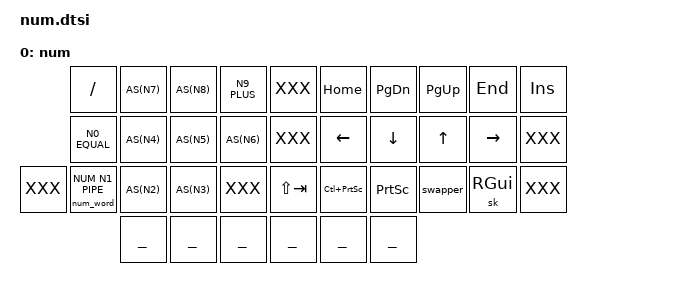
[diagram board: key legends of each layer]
/**
 * Numeric / Navigation Layer
 */

/ {
    keymap {
        compatible = "zmk,keymap";

        num {
            display-name = "num";
            bindings = <
//                ╭─────────────┬─────────────┬─────────────┬─────────────┬─────────────╮   ╭─────────────┬─────────────┬─────────────┬─────────────┬─────────────╮
                   &kp FSLH      AS(N7)        AS(N8)        N9_PLUS       XXX               &kp HOME      &kp PG_DN     &kp PG_UP     &kp END       &kp INS
//                ├─────────────┼─────────────┼─────────────┼─────────────┼─────────────┤   ├─────────────├─────────────┼─────────────┼─────────────┼─────────────┤
                   N0_EQUAL      AS(N4)        AS(N5)        AS(N6)        XXX               &kp LEFT      &kp DOWN      &kp UP        &kp RIGHT     XXX
//  ╭─────────────┬─────────────┼─────────────┼─────────────┼─────────────┼─────────────┤   ├─────────────├─────────────┼─────────────┼─────────────┼─────────────┬─────────────╮
     XXX           &num_word NUM N1_PIPE       AS(N2)        AS(N3)        XXX               &kp LS(TAB)   &kp LC(PSCRN) &kp PSCRN     &swapper      &sk RGUI      XXX
//  ╰─────────────┴─────────────┴─────────────┼─────────────┼─────────────┼─────────────┤   ├─────────────├─────────────┼─────────────┼─────────────┴─────────────┴─────────────╯
                                               ___           ___           ___               ___           ___           ___
//                                            ╰─────────────┴─────────────┴─────────────╯   ╰─────────────┴─────────────┴─────────────╯
            >;
		};
	};
};
